# MPU_PRM register map
Vendor: Texas Instruments
Peripheral module from a debugger description file (folder omap4430).
Registers are 32-bit, access not given, reset 0x3F0707 unless marked. A register's access mark holds for its fields unless they carry their own. Offsets are as the file gives them; lines under a group give offsets from that group; [hi:lo] are bit positions; {n}, {i} and the like mark numbered series; 'fields as' and 'values as' point back to an identical list; <NAME> marks a mode.

## MPU_PRM
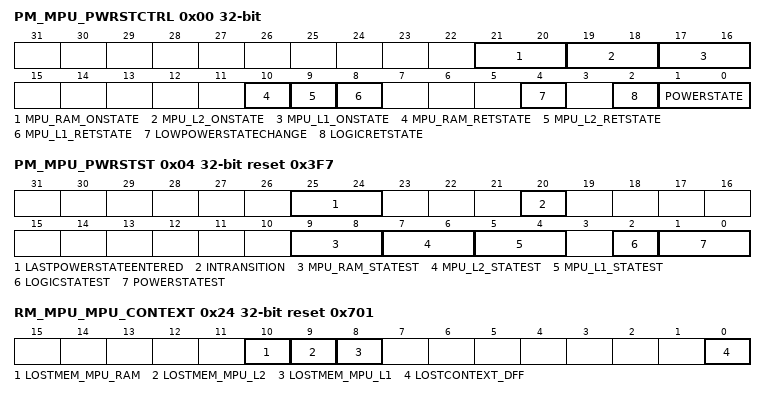
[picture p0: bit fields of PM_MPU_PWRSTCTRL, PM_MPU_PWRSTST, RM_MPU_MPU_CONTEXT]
0x00 PM_MPU_PWRSTCTRL — This register controls the MPU domain power state to reach upon a domain sleep transition
  [21:20] MPU_RAM_ONSTATE — MPU_RAM memory state when domain is ON. (access R Rreturns1s)
    3=MPU_RAM_ONSTATE_3_r (Memory bank is on when the domain is ON.)
  [19:18] MPU_L2_ONSTATE — MPU_L2 memory state when domain is ON. (access R Rreturns1s)
    3=MPU_L2_ONSTATE_3_r (Memory bank is on when the domain is ON.)
  [17:16] MPU_L1_ONSTATE — MPU_L1 memory state when domain is ON. (access R Rreturns1s)
    3=MPU_L1_ONSTATE_3_r (Memory bank is on when the domain is ON.)
  [10] MPU_RAM_RETSTATE — MPU_RAM memory state when domain is RETENTION. (access RO Rreturns1s)
    1=MPU_RAM_RETSTATE_1_r (Memory bank is retained when domain is in RETENTION state.)
  [9] MPU_L2_RETSTATE rw — MPU_L2 memory state when domain is RETENTION.
    0=Memory bank is off when the domain is in the RETENTION state; 1=Memory bank is retained when domain is in RETENTION state
  [8] MPU_L1_RETSTATE rw — MPU_L1 memory state when domain is RETENTION. Should always be same as LogicRETState bit field.
    values as MPU_L2_RETSTATE
  [4] LOWPOWERSTATECHANGE — Power state change request when domain has already performed a sleep transition. Allows going into deeper low power state without waking up the power domain. (access RW WSpecial)
    0=Do not request a low power state change; 1=Request a low power state change. This bit is automatically cleared when the power state is effectively changed or when power state is ON.
  [2] LOGICRETSTATE rw — Logic state when power domain is RETENTION
    0=Only retention registers are retained and remaing logic is off when the domain is in RETENTION state; 1=Whole logic is retained when domain is in RETENTION state
  [1:0] POWERSTATE rw — Power state control.
    0=OFF state; 1=RETENTION state; 2=INACTIVE state; 3=ON State
0x04 PM_MPU_PWRSTST reset 0x3F7 — This register provides a status on the MPU domain current power state. [warm reset insensitive]
  [25:24] LASTPOWERSTATEENTERED — Last low power state entered. Set to 0x3 upon write of the same only. This register is intended for debug purpose only. (access RW W1toSet)
    3=LASTPOWERSTATEENTERED_3_r (Power domain was previously ON-ACTIVE); 2=LASTPOWERSTATEENTERED_2_r (Power domain was previously ON-INACTIVE); 1=LASTPOWERSTATEENTERED_1_r (Power domain was previously in RETENTION); 0=LASTPOWERSTATEENTERED_0_r (Power domain was previously OFF)
  [20] INTRANSITION ro — Domain transition status
    0=INTRANSITION_0_r (No ongoing transition on power domain); 1=INTRANSITION_1_r (Power domain transition is in progress.)
  [9:8] MPU_RAM_STATEST ro — MPU_RAM memory state status
    0=MPU_RAM_STATEST_0_r (Memory is OFF); 1=MPU_RAM_STATEST_1_r (Memory is RETENTION); 2=MPU_RAM_STATEST_2_r (Reserved); 3=MPU_RAM_STATEST_3_r (Memory is ON)
  [7:6] MPU_L2_STATEST ro — MPU_L2 memory state status
    0=MPU_L2_STATEST_0_r (Memory is OFF); 1=MPU_L2_STATEST_1_r (Memory is RETENTION); 2=MPU_L2_STATEST_2_r (Reserved); 3=MPU_L2_STATEST_3_r (Memory is ON)
  [5:4] MPU_L1_STATEST ro — MPU_L1 memory state status
    0=MPU_L1_STATEST_0_r (Memory is OFF); 1=MPU_L1_STATEST_1_r (Reserved); 2=MPU_L1_STATEST_2_r (Reserved); 3=MPU_L1_STATEST_3_r (Memory is ON)
  [2] LOGICSTATEST ro — Logic state status
    0=LOGICSTATEST_0_r (Logic in domain is OFF); 1=LOGICSTATEST_1_r (Logic in domain is ON)
  [1:0] POWERSTATEST ro — Current power state status
    0=POWERSTATEST_0_r (Power domain is OFF); 1=POWERSTATEST_1_r (Power domain is in RETENTION); 2=POWERSTATEST_2_r (Power domain is ON-INACTIVE); 3=POWERSTATEST_3_r (Power domain is ON-ACTIVE)
0x14 RM_MPU_RSTST reset 0x0 — This register logs the different reset sources of the MPU domain. Each bit is set upon release of the domain reset signal. Must be cleared by software. [warm reset insensitive]
  [0] EMULATION_RST — MPU domain has been reset due to emulation reset source, that is, assert reset command initiated by the icepick module (access RW W1toClr)
    0=No emulation reset; 1=The domain has been reset upon emulation reset
0x24 RM_MPU_MPU_CONTEXT reset 0x701 — This register contains dedicated MPU context statuses. [warm reset insensitive]
  [all] fields
    0=Context has been maintained; 1=Context has been lost
  [10] LOSTMEM_MPU_RAM — Specify if memory-based context in MPU_RAM memory bank has been lost due to a previous power transition or other reset source (not affected by a global warm reset). (access RW W1toClr)
  [9] LOSTMEM_MPU_L2 — Specify if memory-based context in MPU_L2 memory bank has been lost due to a previous power transition or other reset source. (access RW W1toClr)
  [8] LOSTMEM_MPU_L1 — Specify if memory-based context in MPU_L1 memory bank has been lost due to a previous power transition or other reset source. Not applicable to Cortex-A9 SMP. (access RW W1toClr)
  [0] LOSTCONTEXT_DFF — Specify if DFF-based context has been lost due to a previous power transition or other reset source. (set upon assertion of MPU_RST signal) (access RW W1toClr)
